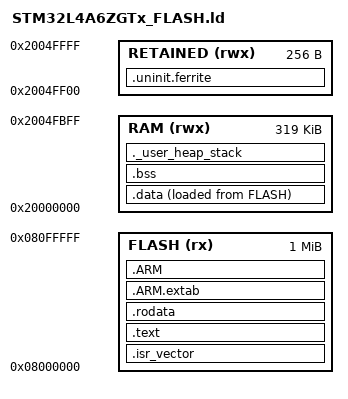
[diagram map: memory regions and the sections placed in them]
/* Linker script for STM32L4A6ZGTx — Nucleo-L4A6ZG */

ENTRY(Reset_Handler)

MEMORY
{
  FLASH (rx)      : ORIGIN = 0x08000000, LENGTH = 1024K
  RAM   (rwx)     : ORIGIN = 0x20000000, LENGTH = 319K
  RETAINED (rwx)  : ORIGIN = 0x2004FF00, LENGTH = 256
}

/* Highest address of the user mode stack — top of RAM minus retained */
_estack = ORIGIN(RAM) + LENGTH(RAM);

/* Minimum heap and stack sizes */
_Min_Heap_Size  = 0x400;
_Min_Stack_Size = 0x800;

SECTIONS
{
  /* Interrupt vector table — must be at start of FLASH */
  .isr_vector :
  {
    . = ALIGN(4);
    KEEP(*(.isr_vector))
    . = ALIGN(4);
  } >FLASH

  /* Code and read-only data */
  .text :
  {
    . = ALIGN(4);
    *(.text)
    *(.text*)
    *(.glue_7)
    *(.glue_7t)
    *(.eh_frame)

    KEEP(*(.init))
    KEEP(*(.fini))

    . = ALIGN(4);
    _etext = .;
  } >FLASH

  /* Constant data */
  .rodata :
  {
    . = ALIGN(4);
    *(.rodata)
    *(.rodata*)
    . = ALIGN(4);
  } >FLASH

  /* ARM exception unwinding */
  .ARM.extab :
  {
    *(.ARM.extab* .gnu.linkonce.armextab.*)
  } >FLASH

  .ARM :
  {
    __exidx_start = .;
    *(.ARM.exidx*)
    __exidx_end = .;
  } >FLASH

  /* Used by startup to initialize .data */
  _sidata = LOADADDR(.data);

  /* Initialized data — loaded from FLASH, copied to RAM at startup */
  .data :
  {
    . = ALIGN(4);
    _sdata = .;
    *(.data)
    *(.data*)
    . = ALIGN(4);
    _edata = .;
  } >RAM AT> FLASH

  /* Zero-initialized data */
  .bss :
  {
    . = ALIGN(4);
    _sbss = .;
    __bss_start__ = _sbss;
    *(.bss)
    *(.bss*)
    *(COMMON)
    . = ALIGN(4);
    _ebss = .;
    __bss_end__ = _ebss;
  } >RAM

  /* Heap */
  ._user_heap_stack :
  {
    . = ALIGN(8);
    PROVIDE(end = .);
    PROVIDE(_end = .);
    . = . + _Min_Heap_Size;
    . = . + _Min_Stack_Size;
    . = ALIGN(8);
  } >RAM

  /* Ferrite retained RAM section — survives warm resets */
  .uninit.ferrite (NOLOAD) :
  {
    . = ALIGN(4);
    _ferrite_retained_start = .;
    KEEP(*(.uninit.ferrite))
    _ferrite_retained_end = .;
    . = ALIGN(4);
  } >RETAINED

  /* Discard debug sections from standard libraries */
  /DISCARD/ :
  {
    libc.a(*)
    libm.a(*)
    libgcc.a(*)
  }

  .ARM.attributes 0 : { *(.ARM.attributes) }
}
